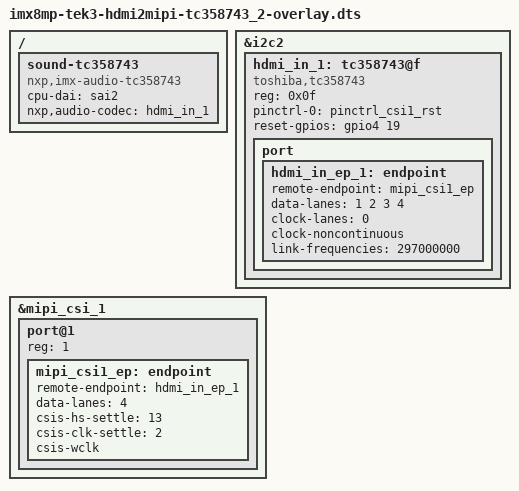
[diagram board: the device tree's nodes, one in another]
// SPDX-License-Identifier: (GPL-2.0+ OR MIT)
/*
 * Copyright 2021 Technexion Ltd.
 *
 * Author: Wig Cheng <wig.cheng@technexion.com>
 *
 */

/dts-v1/;
/plugin/;

#include <dt-bindings/interrupt-controller/irq.h>
#include <dt-bindings/gpio/gpio.h>

/ {
	fragment@0 {
		target = <&i2c2>;
		__overlay__ {
			#address-cells = <1>;
			#size-cells = <0>;
			status = "okay";

			hdmi_in_1: tc358743@f {
				compatible = "toshiba,tc358743";
				reg = <0x0f>;
				pinctrl-names = "default";
				pinctrl-0 = <&pinctrl_csi1_rst>;
				reset-gpios = <&gpio4 19 GPIO_ACTIVE_HIGH>;
				status = "okay";
				port {
					hdmi_in_ep_1: endpoint {
						remote-endpoint = <&mipi_csi1_ep>;
						data-lanes = <1 2 3 4>;
						clock-lanes = <0>;
						clock-noncontinuous;
						link-frequencies = /bits/ 64 <297000000>;
					};
				};
			};
		};
	};

	fragment@1 {
		target = <&mipi_csi_1>;
		__overlay__ {
			#address-cells = <1>;
			#size-cells = <0>;
			status = "okay";
			port@1 {
				reg = <1>;
				mipi_csi1_ep: endpoint {
					remote-endpoint = <&hdmi_in_ep_1>;
					data-lanes = <4>;
					csis-hs-settle = <13>;
					csis-clk-settle = <2>;
					csis-wclk;
				};
			};
		};
	};

	fragment@2 {
		target-path = "/";
		__overlay__ {
			sound-tc358743 {
				compatible = "nxp,imx-audio-tc358743", "nxp,imx-tc358743";
				cpu-dai = <&sai2>;
				nxp,audio-codec = <&hdmi_in_1>;
			};
		};
	};
};

